# MEC1322 register map
Vendor: Microchip Technology Inc.; Series: ARMCM4F; File version: 1.0
CPU: CM4 r1p0, little endian, MPU, FPU, 3 interrupt priority bits
Registers are 32-bit, read-write, reset 0x0 unless marked. A register's access mark holds for its fields unless they carry their own. Offsets are from the block's base; [hi:lo] are bit positions; lines under a group give offsets from that group; {n}, {i} and the like mark numbered series.

## INTS — The interrupt generation logic is made of 16 groups of signals, each of which consist of a Status register, a Enable register and a Result register. The Status and Enable are latched registers. The Result register is a bit by bit AND function of the Source and Enable registers. All the bits of the Result register are OR'ed together and AND'ed with the corresponding bit in the Block. Select register to form the interrupt signal that is routed to the ARM interrupt controller.
Base 0x4000C000
{0x0+0x14*i} IRQ[{i}] (i=0..15) group — DEFINITIONS FOR GIRQ i SOURCE, ENABLE, AND RESULT REGISTERS
  0x00 SOURCE — GIRQx Source Register, R/WC except for reserved bits D31
  0x04 ENABLE_SET — GIRQx Enable Set Register, R/WS except for reserved bits D31. Each GIRQx bit can be individually enabled to assert an interrupt event. 0= Writing a zero has no effect. 1= Writing a one will enable respective GIRQx
  0x08 RESULT ro — GIRQx Result Register. Bits D30 down to D0 are defined in the following subsections reflect the state of the GIRQx interrupt source after the enable bit. The GIRQx result bits are OR'd together to generate the IRQx vector.
  0x0C ENABLE_CLEAR — GIRQx Enable Clear Register. Each GIRQx bit can be individually disabled to assert an interrupt event. 0= Writing a zero has no effect. 1= Writing a one will disable respective GIRQx.
0x200 BLOCK_ENABLE_SET — Block Enable Set Register [23:8] IRQ Vector Enable Set [23:8] Each IRQ Vector can be individually enabled to assert an interrupt event to the EC. 0= Writing a zero has no effect. 1= Writing a one will enable respective IRQi.
0x204 BLOCK_ENABLE_CLEAR — Block Enable Clear Register [23:8] IRQ Vector Enable Clear[23:8] Each IRQ Vector can be individually disabled to assert an interrupt event to the EC. 0= Writing a zero has no effect. 1= Writing a one will disable respective IRQi vector.
0x208 IRQ_VECTOR_STATE ro — Block IRQ Vector Register [23:8] IRQ Vector [23:8] Each read only bit reflects the current state of the IRQ i vector to the EC.

## WDT — The function of the Watchdog Timer is to provide a mechanism to detect if the internal embedded controller has failed. When enabled, the Watchdog Timer (WDT) circuit will generate a WDT Event if the user program fails to reload the WDT within a specified length of time known as the WDT Interval.
Base 0x40000400
0x00 LOAD 16-bit reset 0xF — Writing this field reloads the Watch Dog Timer counter.
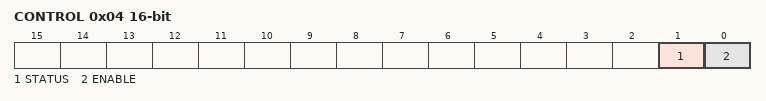
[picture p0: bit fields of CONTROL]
0x04 CONTROL 16-bit — WDT Control Register
  [1] STATUS — WDT_STATUS is set by hardware if the last reset of MEC1322/24 was caused by an underflow of the WDT. This bit must be cleared by the EC firmware writing a '1' to this bit. Writing a '0' to this bit has no effect.
  [0] ENABLE — WDT Block enabled
0x08 KICK 8-bit write — Writes to the WDT Kick Register (WDT_kick) cause the WDT to reload the WDT Load Register (WDT_load) value and start decrementing when the WDT Enable (WDT_enable) bit in the WDT Control Register (WDT_control) is set to '1'. When the WDT Enable (WDT_enable) bit in the WDT Control Register (WDT_control) is cleared to '0', writes to the WDT Kick Register (WDT_kick) have no effect.
0x0C COUNT 16-bit read reset 0xF — This read-only register provide the current WDT count.

## TIMER — This timer block offers a simple mechanism for firmware to maintain a time base. This timer may be instantiated as 16 bits or 32 bits.
Base 0x40000C00
{0x0+0x20*i} CH[{i}] (i=0..5) group — Channel implemented will have these registers to determine that channel's operation.
  0x00 COUNT (reset mask 0xFFFF) — This is the value of the Timer counter. This is updated by Hardware but may be set by Firmware.
  0x04 PRELOAD (reset mask 0xFFFF) — This is the value of the Timer pre-load for the counter. This is used by H/W when the counter is to be restarted automatically; this will become the new value of the counter upon restart.
  0x08 STATUS — This is the interrupt status that fires when the timer reaches its limit. (R/WC)
    [0] INT_EVT
  0x0C INT_EN — This is the interrupt enable for the status EVENT_INTERRUPT bit in the Timer Status Register
    [0] ENABLE
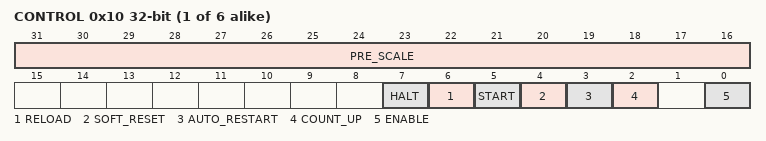
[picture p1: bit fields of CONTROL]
  0x10 CONTROL (reset mask 0xFFFF) — Timer Control Register
    [31:16] PRE_SCALE — This is used to divide down the system clock through clock enables to lower the power consumption of the block and allow slow timers.
    [7] HALT — This is a halt bit. This will halt the timer as long as it is active.
    [6] RELOAD — This bit reloads the counter without interrupting it operation. This will not function if the timer has already completed (when the START bit in this register is '0').
    [5] START — This bit triggers the timer counter.
    [4] SOFT_RESET — This is a soft reset. This is self clearing 1 cycle after it is written.
    [3] AUTO_RESTART — This will select the action taken upon completing a count.
    [2] COUNT_UP — This selects the counter direction.
    [0] ENABLE — This enables the block for operation.
